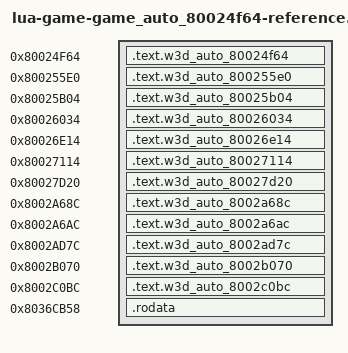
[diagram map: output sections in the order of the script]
/* Generated reference-only placements. All bodies are source-built. */
OUTPUT_FORMAT("elf32-powerpc")
OUTPUT_ARCH(powerpc)
ENTRY(w3d_auto_80024f64)
_SDA_BASE_ = 0x804b2540;
_SDA2_BASE_ = 0x804c2540;
fn_800261D4 = 0x800261d4;
fn_800271EC = 0x800271ec;
fn_8002A6CC = 0x8002a6cc;
fn_8002AF78 = 0x8002af78;
fn_8006E71C = 0x8006e71c;
fn_800FC1B0 = 0x800fc1b0;
fn_800FC6DC = 0x800fc6dc;
fn_8015FD1C = 0x8015fd1c;
fn_80178C48 = 0x80178c48;
fn_80178DF0 = 0x80178df0;
fn_803426B4 = 0x803426b4;
fn_80342A74 = 0x80342a74;
SECTIONS {
  .text.w3d_auto_80024f64 0x80024f64 : { *(.text.w3d_auto_80024f64) }
  .text.w3d_auto_800255e0 0x800255e0 : { *(.text.w3d_auto_800255e0) }
  .text.w3d_auto_80025b04 0x80025b04 : { *(.text.w3d_auto_80025b04) }
  .text.w3d_auto_80026034 0x80026034 : { *(.text.w3d_auto_80026034) }
  .text.w3d_auto_80026e14 0x80026e14 : { *(.text.w3d_auto_80026e14) }
  .text.w3d_auto_80027114 0x80027114 : { *(.text.w3d_auto_80027114) }
  .text.w3d_auto_80027d20 0x80027d20 : { *(.text.w3d_auto_80027d20) }
  .text.w3d_auto_8002a68c 0x8002a68c : { *(.text.w3d_auto_8002a68c) }
  .text.w3d_auto_8002a6ac 0x8002a6ac : { *(.text.w3d_auto_8002a6ac) }
  .text.w3d_auto_8002ad7c 0x8002ad7c : { *(.text.w3d_auto_8002ad7c) }
  .text.w3d_auto_8002b070 0x8002b070 : { *(.text.w3d_auto_8002b070) }
  .text.w3d_auto_8002c0bc 0x8002c0bc : { *(.text.w3d_auto_8002c0bc) }
  .rodata 0x8036cb58 : { *(.rodata) }
  /DISCARD/ : { *(.text*) *(.rodata*) *(.data*) *(.bss*) *(.sdata*) *(.sbss*) *(.comment) }
}
